# CBASS0_ISC register map
Vendor: Texas Instruments
Registers are 32-bit, read-write, reset 0x0 unless marked. A register's access mark holds for its fields unless they carry their own. Offsets are as the file gives them; [hi:lo] are bit positions; {n}, {i} and the like mark numbered series; 'fields as' and 'values as' point back to an identical list.

## CBASS0_ISC (part 2 of 2)
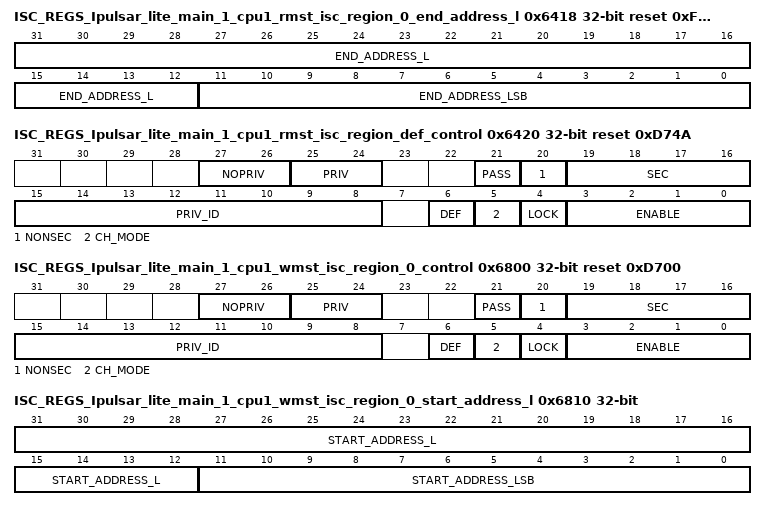
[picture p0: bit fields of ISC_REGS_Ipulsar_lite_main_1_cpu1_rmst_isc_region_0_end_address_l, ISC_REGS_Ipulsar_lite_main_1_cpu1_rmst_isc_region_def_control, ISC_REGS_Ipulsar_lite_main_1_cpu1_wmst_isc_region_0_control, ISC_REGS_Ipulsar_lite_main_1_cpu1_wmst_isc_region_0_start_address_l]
0x6418 ISC_REGS_Ipulsar_lite_main_1_cpu1_rmst_isc_region_0_end_address_l access per field reset 0xFFF — The ISC Region 0 End Address Low Register defines the end included address bits 31 to 0 for the master Ipulsar_lite_main_1.cpu1_rmst region 0 ISC.
  [31:12] END_ADDRESS_L rw — End address bits 31 to 12 to include in the match.
  [11:0] END_ADDRESS_LSB ro — End address bits 11 to 0 are forced to Fs as address must be 4KB aligned.
0x641C ISC_REGS_Ipulsar_lite_main_1_cpu1_rmst_isc_region_0_end_address_h — The ISC Region 0 End Address High Register defines the end address bits 47 to 32 for the master Ipulsar_lite_main_1.cpu1_rmst region 0 ISC.
  [15:0] END_ADDRESS_H — End address bits 47 to 32.
0x6420 ISC_REGS_Ipulsar_lite_main_1_cpu1_rmst_isc_region_def_control access not given reset 0xD74A — The ISC Default Region Control Register defines the control fields for the master Ipulsar_lite_main_1.cpu1_rmst region 1 ISC.
  [27:26] NOPRIV rw — Clear output priv attribute. If each bit is set then the outgoing priv bit is cleared, else the bit is unchanged. Do not set both priv and nopriv for the same bit.
  [25:24] PRIV rw — Set outgoing priv attribute. If each bit is set then the outgoing priv bit is set, else the bit is unchanged. Do not set both priv and nopriv for the same bit.
  [21] PASS rw — No privID replacement. A value of 1 will pass through privid value. A value of 0 will replace privid with priv_id field value.
  [20] NONSEC rw — Make outgoing non-secure. A value of 1 forces secure clear, others do nothing. Do not set both sec and nonsec.
  [19:16] SEC rw — Make outgoing secure. A value of 0xA forces secure set, others do nothing. Do not set both sec and nonsec.
  [15:8] PRIV_ID rw — Priv ID value to use if pass is 0.
  [6] DEF ro — Default region indication. The default region is used when all other regions do not match.
  [5] CH_MODE ro — Enable channel mode to match region to a chanid value. Otherwise use address mode to match region to an address range.
  [4] LOCK — Lock region. Once set, the region values cannot be modified. (access R/W1TS)
  [3:0] ENABLE ro — Enable region. A value of 0xA enables, others disable.
0x6800 ISC_REGS_Ipulsar_lite_main_1_cpu1_wmst_isc_region_0_control access not given reset 0xD700 — The ISC Region 0 Control Register defines the control fields for the master Ipulsar_lite_main_1.cpu1_wmst region 0 ISC.
  [27:26] NOPRIV rw — Clear output priv attribute. If each bit is set then the outgoing priv bit is cleared.
  [25:24] PRIV rw — Set outgoing priv attribute. If each bit is set then the outgoing priv bit is set.
  [21] PASS rw — No privID replacement, pass through value.
  [20] NONSEC rw — Make outgoing non-secure.
  [19:16] SEC rw — Make outgoing secure. A value of 0xA enables, others disable.
  [15:8] PRIV_ID rw
  [6] DEF ro — Default region indication. The default region is used when all other regions do not match.
  [5] CH_MODE rw — Enable channel mode to match region to a chanid value. Otherwise use address mode to match region to an address range.
  [4] LOCK — Lock region. Once set the region values cannot be modified. (access R/W1TS)
  [3:0] ENABLE rw — Enable region. A value of 0xA enables, others disable.
0x6810 ISC_REGS_Ipulsar_lite_main_1_cpu1_wmst_isc_region_0_start_address_l — The ISC Region 0 Start Address Low Register defines the start address bits 31 to 0 for the master Ipulsar_lite_main_1.cpu1_wmst region 0 ISC.
  [31:12] START_ADDRESS_L — Start address bits 31 to 12.
  [11:0] START_ADDRESS_LSB — Start address bits 11 to 0 must be 0 as address must be 4KB aligned in address mode. Can also be channel number in channel mode.
0x6814 ISC_REGS_Ipulsar_lite_main_1_cpu1_wmst_isc_region_0_start_address_h — The ISC Region 0 Start Address High Register defines the start address bits 47 to 32 for the master Ipulsar_lite_main_1.cpu1_wmst region 0 ISC.
  [15:0] START_ADDRESS_H — Start address bits 47 to 32.
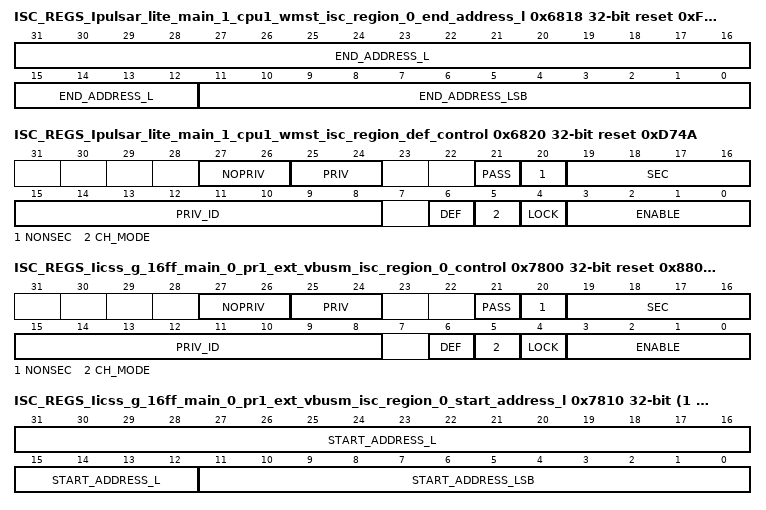
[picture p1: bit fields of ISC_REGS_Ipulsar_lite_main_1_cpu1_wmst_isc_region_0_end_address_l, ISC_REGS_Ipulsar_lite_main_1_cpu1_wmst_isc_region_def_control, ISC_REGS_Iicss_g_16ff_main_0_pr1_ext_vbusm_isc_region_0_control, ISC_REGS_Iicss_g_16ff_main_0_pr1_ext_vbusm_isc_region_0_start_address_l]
0x6818 ISC_REGS_Ipulsar_lite_main_1_cpu1_wmst_isc_region_0_end_address_l access per field reset 0xFFF — The ISC Region 0 End Address Low Register defines the end included address bits 31 to 0 for the master Ipulsar_lite_main_1.cpu1_wmst region 0 ISC.
  fields as ISC_REGS_Ipulsar_lite_main_1_cpu1_rmst_isc_region_0_end_address_l
0x681C ISC_REGS_Ipulsar_lite_main_1_cpu1_wmst_isc_region_0_end_address_h — The ISC Region 0 End Address High Register defines the end address bits 47 to 32 for the master Ipulsar_lite_main_1.cpu1_wmst region 0 ISC.
  [15:0] END_ADDRESS_H — End address bits 47 to 32.
0x6820 ISC_REGS_Ipulsar_lite_main_1_cpu1_wmst_isc_region_def_control access not given reset 0xD74A — The ISC Default Region Control Register defines the control fields for the master Ipulsar_lite_main_1.cpu1_wmst region 1 ISC.
  fields as ISC_REGS_Ipulsar_lite_main_1_cpu1_rmst_isc_region_def_control
{0x7800+0x20*i} ISC_REGS_Iicss_g_16ff_main_0_pr1_ext_vbusm_isc_region_{i}_control access not given reset 0x8800 (i=0..15) — The ISC Region {i} Control Register defines the control fields for the master Iicss_g_16ff_main_0.pr1_ext_vbusm region {i} ISC.
  fields as ISC_REGS_Ipulsar_lite_main_1_cpu1_wmst_isc_region_0_control
{0x7810+0x20*i} ISC_REGS_Iicss_g_16ff_main_0_pr1_ext_vbusm_isc_region_{i}_start_address_l (i=0..15) — The ISC Region {i} Start Address Low Register defines the start address bits 31 to 0 for the master Iicss_g_16ff_main_0.pr1_ext_vbusm region {i} ISC.
  fields as ISC_REGS_Ipulsar_lite_main_1_cpu1_wmst_isc_region_0_start_address_l
{0x7814+0x20*i} ISC_REGS_Iicss_g_16ff_main_0_pr1_ext_vbusm_isc_region_{i}_start_address_h (i=0..15) — The ISC Region {i} Start Address High Register defines the start address bits 47 to 32 for the master Iicss_g_16ff_main_0.pr1_ext_vbusm region {i} ISC.
  [15:0] START_ADDRESS_H — Start address bits 47 to 32.
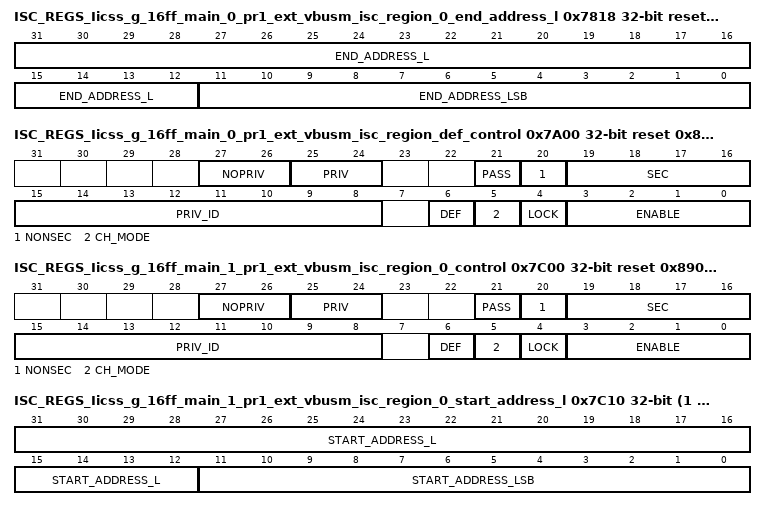
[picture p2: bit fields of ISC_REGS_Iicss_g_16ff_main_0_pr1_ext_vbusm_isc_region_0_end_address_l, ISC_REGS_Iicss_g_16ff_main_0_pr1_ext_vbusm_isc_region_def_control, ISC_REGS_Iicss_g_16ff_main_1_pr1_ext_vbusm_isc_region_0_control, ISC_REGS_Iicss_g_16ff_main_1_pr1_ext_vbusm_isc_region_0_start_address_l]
{0x7818+0x20*i} ISC_REGS_Iicss_g_16ff_main_0_pr1_ext_vbusm_isc_region_{i}_end_address_l access per field reset 0xFFF (i=0..15) — The ISC Region {i} End Address Low Register defines the end included address bits 31 to 0 for the master Iicss_g_16ff_main_0.pr1_ext_vbusm region {i} ISC.
  fields as ISC_REGS_Ipulsar_lite_main_1_cpu1_rmst_isc_region_0_end_address_l
{0x781C+0x20*i} ISC_REGS_Iicss_g_16ff_main_0_pr1_ext_vbusm_isc_region_{i}_end_address_h (i=0..15) — The ISC Region {i} End Address High Register defines the end address bits 47 to 32 for the master Iicss_g_16ff_main_0.pr1_ext_vbusm region {i} ISC.
  [15:0] END_ADDRESS_H — End address bits 47 to 32.
0x7A00 ISC_REGS_Iicss_g_16ff_main_0_pr1_ext_vbusm_isc_region_def_control access not given reset 0x884A — The ISC Default Region Control Register defines the control fields for the master Iicss_g_16ff_main_0.pr1_ext_vbusm region 16 ISC.
  fields as ISC_REGS_Ipulsar_lite_main_1_cpu1_rmst_isc_region_def_control
{0x7C00+0x20*i} ISC_REGS_Iicss_g_16ff_main_1_pr1_ext_vbusm_isc_region_{i}_control access not given reset 0x8900 (i=0..15) — The ISC Region {i} Control Register defines the control fields for the master Iicss_g_16ff_main_1.pr1_ext_vbusm region {i} ISC.
  fields as ISC_REGS_Ipulsar_lite_main_1_cpu1_wmst_isc_region_0_control
{0x7C10+0x20*i} ISC_REGS_Iicss_g_16ff_main_1_pr1_ext_vbusm_isc_region_{i}_start_address_l (i=0..15) — The ISC Region {i} Start Address Low Register defines the start address bits 31 to 0 for the master Iicss_g_16ff_main_1.pr1_ext_vbusm region {i} ISC.
  fields as ISC_REGS_Ipulsar_lite_main_1_cpu1_wmst_isc_region_0_start_address_l
{0x7C14+0x20*i} ISC_REGS_Iicss_g_16ff_main_1_pr1_ext_vbusm_isc_region_{i}_start_address_h (i=0..15) — The ISC Region {i} Start Address High Register defines the start address bits 47 to 32 for the master Iicss_g_16ff_main_1.pr1_ext_vbusm region {i} ISC.
  [15:0] START_ADDRESS_H — Start address bits 47 to 32.
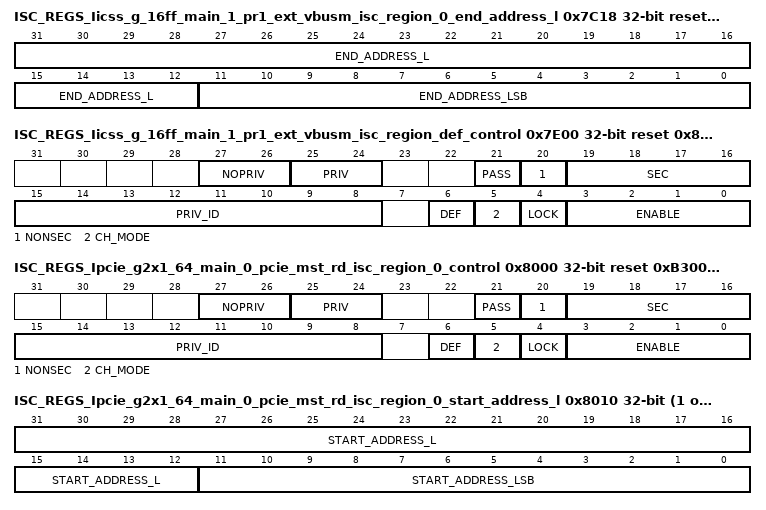
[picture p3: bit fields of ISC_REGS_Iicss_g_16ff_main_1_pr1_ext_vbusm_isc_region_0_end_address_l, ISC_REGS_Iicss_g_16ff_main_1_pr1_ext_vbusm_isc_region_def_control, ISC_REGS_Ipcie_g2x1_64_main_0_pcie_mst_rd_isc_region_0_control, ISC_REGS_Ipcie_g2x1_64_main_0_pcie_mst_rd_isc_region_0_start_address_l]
{0x7C18+0x20*i} ISC_REGS_Iicss_g_16ff_main_1_pr1_ext_vbusm_isc_region_{i}_end_address_l access per field reset 0xFFF (i=0..15) — The ISC Region {i} End Address Low Register defines the end included address bits 31 to 0 for the master Iicss_g_16ff_main_1.pr1_ext_vbusm region {i} ISC.
  fields as ISC_REGS_Ipulsar_lite_main_1_cpu1_rmst_isc_region_0_end_address_l
{0x7C1C+0x20*i} ISC_REGS_Iicss_g_16ff_main_1_pr1_ext_vbusm_isc_region_{i}_end_address_h (i=0..15) — The ISC Region {i} End Address High Register defines the end address bits 47 to 32 for the master Iicss_g_16ff_main_1.pr1_ext_vbusm region {i} ISC.
  [15:0] END_ADDRESS_H — End address bits 47 to 32.
0x7E00 ISC_REGS_Iicss_g_16ff_main_1_pr1_ext_vbusm_isc_region_def_control access not given reset 0x894A — The ISC Default Region Control Register defines the control fields for the master Iicss_g_16ff_main_1.pr1_ext_vbusm region 16 ISC.
  fields as ISC_REGS_Ipulsar_lite_main_1_cpu1_rmst_isc_region_def_control
{0x8000+0x20*i} ISC_REGS_Ipcie_g2x1_64_main_0_pcie_mst_rd_isc_region_{i}_control access not given reset 0xB300 (i=0..7) — The ISC Region {i} Control Register defines the control fields for the master Ipcie_g2x1_64_main_0.pcie_mst_rd region {i} ISC.
  fields as ISC_REGS_Ipulsar_lite_main_1_cpu1_wmst_isc_region_0_control
{0x8010+0x20*i} ISC_REGS_Ipcie_g2x1_64_main_0_pcie_mst_rd_isc_region_{i}_start_address_l (i=0..7) — The ISC Region {i} Start Address Low Register defines the start address bits 31 to 0 for the master Ipcie_g2x1_64_main_0.pcie_mst_rd region {i} ISC.
  fields as ISC_REGS_Ipulsar_lite_main_1_cpu1_wmst_isc_region_0_start_address_l
{0x8014+0x20*i} ISC_REGS_Ipcie_g2x1_64_main_0_pcie_mst_rd_isc_region_{i}_start_address_h (i=0..7) — The ISC Region {i} Start Address High Register defines the start address bits 47 to 32 for the master Ipcie_g2x1_64_main_0.pcie_mst_rd region {i} ISC.
  [15:0] START_ADDRESS_H — Start address bits 47 to 32.
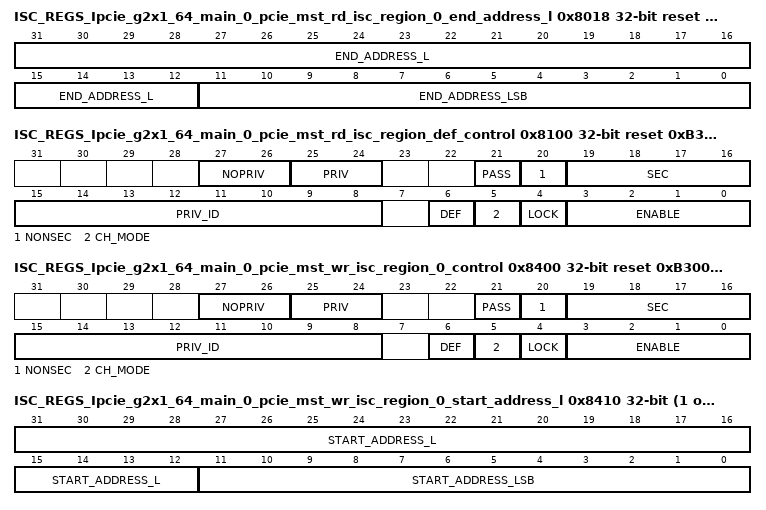
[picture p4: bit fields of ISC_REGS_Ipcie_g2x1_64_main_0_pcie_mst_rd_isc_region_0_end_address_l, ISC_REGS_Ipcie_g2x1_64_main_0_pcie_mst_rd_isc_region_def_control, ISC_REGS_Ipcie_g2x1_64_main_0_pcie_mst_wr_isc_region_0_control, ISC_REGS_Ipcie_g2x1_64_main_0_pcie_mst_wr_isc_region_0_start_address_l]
{0x8018+0x20*i} ISC_REGS_Ipcie_g2x1_64_main_0_pcie_mst_rd_isc_region_{i}_end_address_l access per field reset 0xFFF (i=0..7) — The ISC Region {i} End Address Low Register defines the end included address bits 31 to 0 for the master Ipcie_g2x1_64_main_0.pcie_mst_rd region {i} ISC.
  fields as ISC_REGS_Ipulsar_lite_main_1_cpu1_rmst_isc_region_0_end_address_l
{0x801C+0x20*i} ISC_REGS_Ipcie_g2x1_64_main_0_pcie_mst_rd_isc_region_{i}_end_address_h (i=0..7) — The ISC Region {i} End Address High Register defines the end address bits 47 to 32 for the master Ipcie_g2x1_64_main_0.pcie_mst_rd region {i} ISC.
  [15:0] END_ADDRESS_H — End address bits 47 to 32.
0x8100 ISC_REGS_Ipcie_g2x1_64_main_0_pcie_mst_rd_isc_region_def_control access not given reset 0xB34A — The ISC Default Region Control Register defines the control fields for the master Ipcie_g2x1_64_main_0.pcie_mst_rd region 8 ISC.
  fields as ISC_REGS_Ipulsar_lite_main_1_cpu1_rmst_isc_region_def_control
{0x8400+0x20*i} ISC_REGS_Ipcie_g2x1_64_main_0_pcie_mst_wr_isc_region_{i}_control access not given reset 0xB300 (i=0..7) — The ISC Region {i} Control Register defines the control fields for the master Ipcie_g2x1_64_main_0.pcie_mst_wr region {i} ISC.
  fields as ISC_REGS_Ipulsar_lite_main_1_cpu1_wmst_isc_region_0_control
{0x8410+0x20*i} ISC_REGS_Ipcie_g2x1_64_main_0_pcie_mst_wr_isc_region_{i}_start_address_l (i=0..7) — The ISC Region {i} Start Address Low Register defines the start address bits 31 to 0 for the master Ipcie_g2x1_64_main_0.pcie_mst_wr region {i} ISC.
  fields as ISC_REGS_Ipulsar_lite_main_1_cpu1_wmst_isc_region_0_start_address_l
{0x8414+0x20*i} ISC_REGS_Ipcie_g2x1_64_main_0_pcie_mst_wr_isc_region_{i}_start_address_h (i=0..7) — The ISC Region {i} Start Address High Register defines the start address bits 47 to 32 for the master Ipcie_g2x1_64_main_0.pcie_mst_wr region {i} ISC.
  [15:0] START_ADDRESS_H — Start address bits 47 to 32.
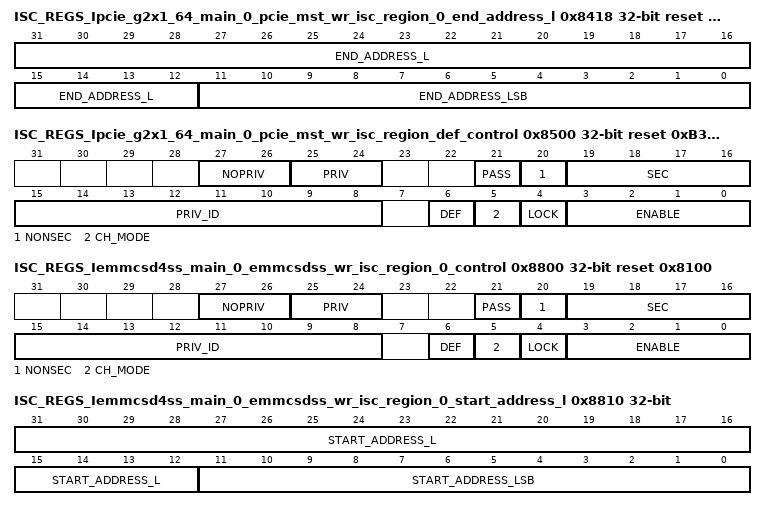
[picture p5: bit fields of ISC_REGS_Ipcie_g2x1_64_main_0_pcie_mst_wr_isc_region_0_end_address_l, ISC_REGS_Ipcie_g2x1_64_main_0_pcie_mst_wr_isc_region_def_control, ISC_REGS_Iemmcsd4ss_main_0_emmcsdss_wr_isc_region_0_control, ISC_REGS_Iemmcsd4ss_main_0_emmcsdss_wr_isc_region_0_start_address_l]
{0x8418+0x20*i} ISC_REGS_Ipcie_g2x1_64_main_0_pcie_mst_wr_isc_region_{i}_end_address_l access per field reset 0xFFF (i=0..7) — The ISC Region {i} End Address Low Register defines the end included address bits 31 to 0 for the master Ipcie_g2x1_64_main_0.pcie_mst_wr region {i} ISC.
  fields as ISC_REGS_Ipulsar_lite_main_1_cpu1_rmst_isc_region_0_end_address_l
{0x841C+0x20*i} ISC_REGS_Ipcie_g2x1_64_main_0_pcie_mst_wr_isc_region_{i}_end_address_h (i=0..7) — The ISC Region {i} End Address High Register defines the end address bits 47 to 32 for the master Ipcie_g2x1_64_main_0.pcie_mst_wr region {i} ISC.
  [15:0] END_ADDRESS_H — End address bits 47 to 32.
0x8500 ISC_REGS_Ipcie_g2x1_64_main_0_pcie_mst_wr_isc_region_def_control access not given reset 0xB34A — The ISC Default Region Control Register defines the control fields for the master Ipcie_g2x1_64_main_0.pcie_mst_wr region 8 ISC.
  fields as ISC_REGS_Ipulsar_lite_main_1_cpu1_rmst_isc_region_def_control
0x8800 ISC_REGS_Iemmcsd4ss_main_0_emmcsdss_wr_isc_region_0_control access not given reset 0x8100 — The ISC Region 0 Control Register defines the control fields for the master Iemmcsd4ss_main_0.emmcsdss_wr region 0 ISC.
  fields as ISC_REGS_Ipulsar_lite_main_1_cpu1_wmst_isc_region_0_control
0x8810 ISC_REGS_Iemmcsd4ss_main_0_emmcsdss_wr_isc_region_0_start_address_l — The ISC Region 0 Start Address Low Register defines the start address bits 31 to 0 for the master Iemmcsd4ss_main_0.emmcsdss_wr region 0 ISC.
  fields as ISC_REGS_Ipulsar_lite_main_1_cpu1_wmst_isc_region_0_start_address_l
0x8814 ISC_REGS_Iemmcsd4ss_main_0_emmcsdss_wr_isc_region_0_start_address_h — The ISC Region 0 Start Address High Register defines the start address bits 47 to 32 for the master Iemmcsd4ss_main_0.emmcsdss_wr region 0 ISC.
  [15:0] START_ADDRESS_H — Start address bits 47 to 32.
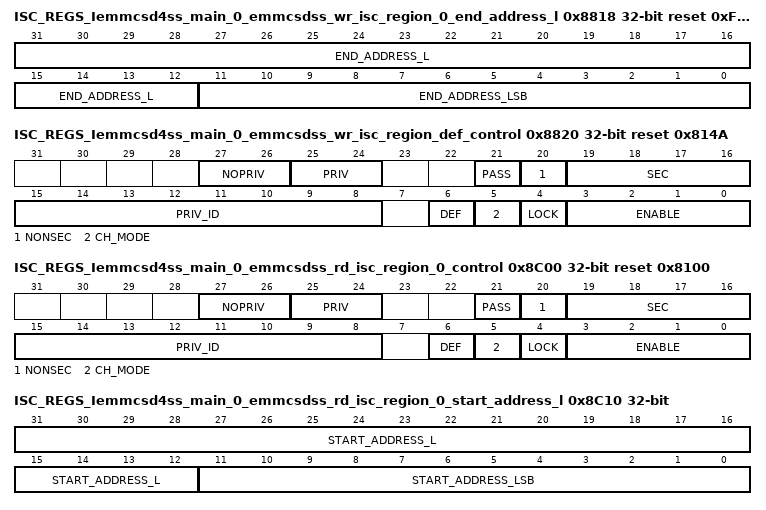
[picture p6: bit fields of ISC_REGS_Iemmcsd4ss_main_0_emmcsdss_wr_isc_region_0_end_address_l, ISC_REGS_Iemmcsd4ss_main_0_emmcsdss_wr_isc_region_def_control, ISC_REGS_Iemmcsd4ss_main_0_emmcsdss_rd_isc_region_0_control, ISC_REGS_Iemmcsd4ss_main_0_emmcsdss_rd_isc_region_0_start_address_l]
0x8818 ISC_REGS_Iemmcsd4ss_main_0_emmcsdss_wr_isc_region_0_end_address_l access per field reset 0xFFF — The ISC Region 0 End Address Low Register defines the end included address bits 31 to 0 for the master Iemmcsd4ss_main_0.emmcsdss_wr region 0 ISC.
  fields as ISC_REGS_Ipulsar_lite_main_1_cpu1_rmst_isc_region_0_end_address_l
0x881C ISC_REGS_Iemmcsd4ss_main_0_emmcsdss_wr_isc_region_0_end_address_h — The ISC Region 0 End Address High Register defines the end address bits 47 to 32 for the master Iemmcsd4ss_main_0.emmcsdss_wr region 0 ISC.
  [15:0] END_ADDRESS_H — End address bits 47 to 32.
0x8820 ISC_REGS_Iemmcsd4ss_main_0_emmcsdss_wr_isc_region_def_control access not given reset 0x814A — The ISC Default Region Control Register defines the control fields for the master Iemmcsd4ss_main_0.emmcsdss_wr region 1 ISC.
  fields as ISC_REGS_Ipulsar_lite_main_1_cpu1_rmst_isc_region_def_control
0x8C00 ISC_REGS_Iemmcsd4ss_main_0_emmcsdss_rd_isc_region_0_control access not given reset 0x8100 — The ISC Region 0 Control Register defines the control fields for the master Iemmcsd4ss_main_0.emmcsdss_rd region 0 ISC.
  fields as ISC_REGS_Ipulsar_lite_main_1_cpu1_wmst_isc_region_0_control
0x8C10 ISC_REGS_Iemmcsd4ss_main_0_emmcsdss_rd_isc_region_0_start_address_l — The ISC Region 0 Start Address Low Register defines the start address bits 31 to 0 for the master Iemmcsd4ss_main_0.emmcsdss_rd region 0 ISC.
  fields as ISC_REGS_Ipulsar_lite_main_1_cpu1_wmst_isc_region_0_start_address_l
0x8C14 ISC_REGS_Iemmcsd4ss_main_0_emmcsdss_rd_isc_region_0_start_address_h — The ISC Region 0 Start Address High Register defines the start address bits 47 to 32 for the master Iemmcsd4ss_main_0.emmcsdss_rd region 0 ISC.
  [15:0] START_ADDRESS_H — Start address bits 47 to 32.
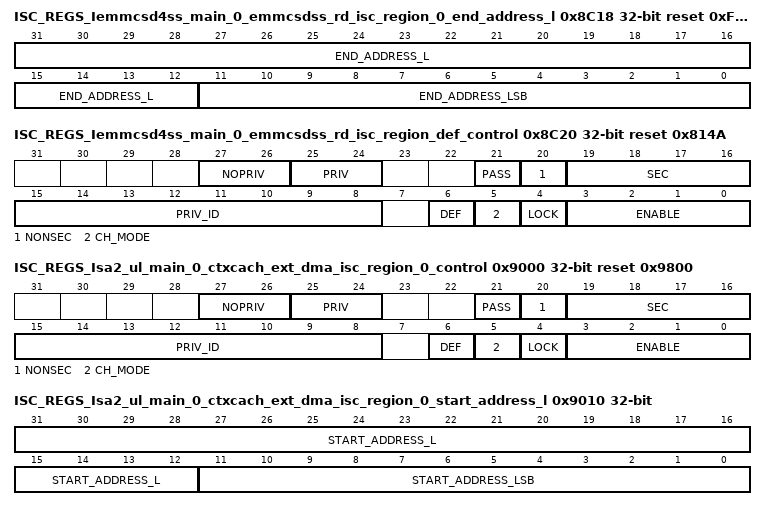
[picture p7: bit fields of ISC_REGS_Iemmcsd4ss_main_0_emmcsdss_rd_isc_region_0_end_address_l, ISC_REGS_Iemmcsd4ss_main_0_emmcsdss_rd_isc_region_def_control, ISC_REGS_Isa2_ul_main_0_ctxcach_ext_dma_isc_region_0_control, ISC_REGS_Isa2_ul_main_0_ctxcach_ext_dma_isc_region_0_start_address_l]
0x8C18 ISC_REGS_Iemmcsd4ss_main_0_emmcsdss_rd_isc_region_0_end_address_l access per field reset 0xFFF — The ISC Region 0 End Address Low Register defines the end included address bits 31 to 0 for the master Iemmcsd4ss_main_0.emmcsdss_rd region 0 ISC.
  fields as ISC_REGS_Ipulsar_lite_main_1_cpu1_rmst_isc_region_0_end_address_l
0x8C1C ISC_REGS_Iemmcsd4ss_main_0_emmcsdss_rd_isc_region_0_end_address_h — The ISC Region 0 End Address High Register defines the end address bits 47 to 32 for the master Iemmcsd4ss_main_0.emmcsdss_rd region 0 ISC.
  [15:0] END_ADDRESS_H — End address bits 47 to 32.
0x8C20 ISC_REGS_Iemmcsd4ss_main_0_emmcsdss_rd_isc_region_def_control access not given reset 0x814A — The ISC Default Region Control Register defines the control fields for the master Iemmcsd4ss_main_0.emmcsdss_rd region 1 ISC.
  fields as ISC_REGS_Ipulsar_lite_main_1_cpu1_rmst_isc_region_def_control
0x9000 ISC_REGS_Isa2_ul_main_0_ctxcach_ext_dma_isc_region_0_control access not given reset 0x9800 — The ISC Region 0 Control Register defines the control fields for the master Isa2_ul_main_0.ctxcach_ext_dma region 0 ISC.
  fields as ISC_REGS_Ipulsar_lite_main_1_cpu1_wmst_isc_region_0_control
0x9010 ISC_REGS_Isa2_ul_main_0_ctxcach_ext_dma_isc_region_0_start_address_l — The ISC Region 0 Start Address Low Register defines the start address bits 31 to 0 for the master Isa2_ul_main_0.ctxcach_ext_dma region 0 ISC.
  fields as ISC_REGS_Ipulsar_lite_main_1_cpu1_wmst_isc_region_0_start_address_l
0x9014 ISC_REGS_Isa2_ul_main_0_ctxcach_ext_dma_isc_region_0_start_address_h — The ISC Region 0 Start Address High Register defines the start address bits 47 to 32 for the master Isa2_ul_main_0.ctxcach_ext_dma region 0 ISC.
  [15:0] START_ADDRESS_H — Start address bits 47 to 32.
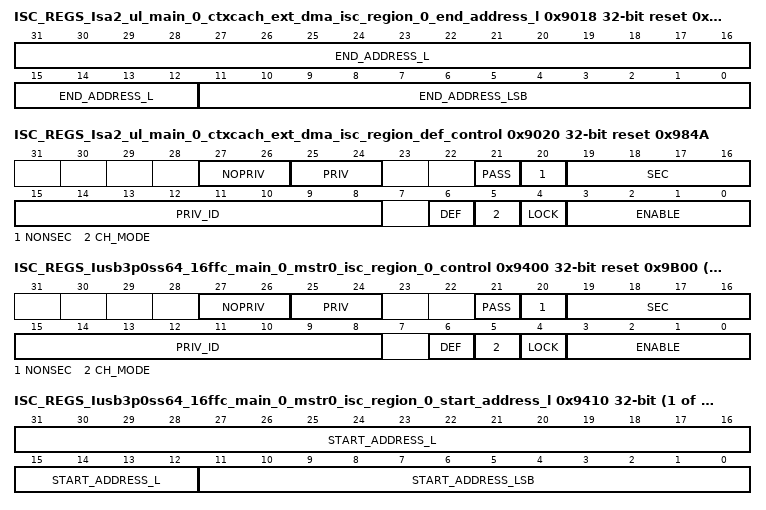
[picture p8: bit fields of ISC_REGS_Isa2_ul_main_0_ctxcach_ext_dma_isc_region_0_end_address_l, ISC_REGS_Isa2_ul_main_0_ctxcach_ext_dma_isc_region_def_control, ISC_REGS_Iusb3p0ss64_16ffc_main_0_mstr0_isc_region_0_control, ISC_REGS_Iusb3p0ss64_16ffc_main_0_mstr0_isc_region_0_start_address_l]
0x9018 ISC_REGS_Isa2_ul_main_0_ctxcach_ext_dma_isc_region_0_end_address_l access per field reset 0xFFF — The ISC Region 0 End Address Low Register defines the end included address bits 31 to 0 for the master Isa2_ul_main_0.ctxcach_ext_dma region 0 ISC.
  fields as ISC_REGS_Ipulsar_lite_main_1_cpu1_rmst_isc_region_0_end_address_l
0x901C ISC_REGS_Isa2_ul_main_0_ctxcach_ext_dma_isc_region_0_end_address_h — The ISC Region 0 End Address High Register defines the end address bits 47 to 32 for the master Isa2_ul_main_0.ctxcach_ext_dma region 0 ISC.
  [15:0] END_ADDRESS_H — End address bits 47 to 32.
0x9020 ISC_REGS_Isa2_ul_main_0_ctxcach_ext_dma_isc_region_def_control access not given reset 0x984A — The ISC Default Region Control Register defines the control fields for the master Isa2_ul_main_0.ctxcach_ext_dma region 1 ISC.
  fields as ISC_REGS_Ipulsar_lite_main_1_cpu1_rmst_isc_region_def_control
{0x9400+0x20*i} ISC_REGS_Iusb3p0ss64_16ffc_main_0_mstr0_isc_region_{i}_control access not given reset 0x9B00 (i=0..7) — The ISC Region {i} Control Register defines the control fields for the master Iusb3p0ss64_16ffc_main_0.mstr0 region {i} ISC.
  fields as ISC_REGS_Ipulsar_lite_main_1_cpu1_wmst_isc_region_0_control
{0x9410+0x20*i} ISC_REGS_Iusb3p0ss64_16ffc_main_0_mstr0_isc_region_{i}_start_address_l (i=0..7) — The ISC Region {i} Start Address Low Register defines the start address bits 31 to 0 for the master Iusb3p0ss64_16ffc_main_0.mstr0 region {i} ISC.
  fields as ISC_REGS_Ipulsar_lite_main_1_cpu1_wmst_isc_region_0_start_address_l
{0x9414+0x20*i} ISC_REGS_Iusb3p0ss64_16ffc_main_0_mstr0_isc_region_{i}_start_address_h (i=0..7) — The ISC Region {i} Start Address High Register defines the start address bits 47 to 32 for the master Iusb3p0ss64_16ffc_main_0.mstr0 region {i} ISC.
  [15:0] START_ADDRESS_H — Start address bits 47 to 32.
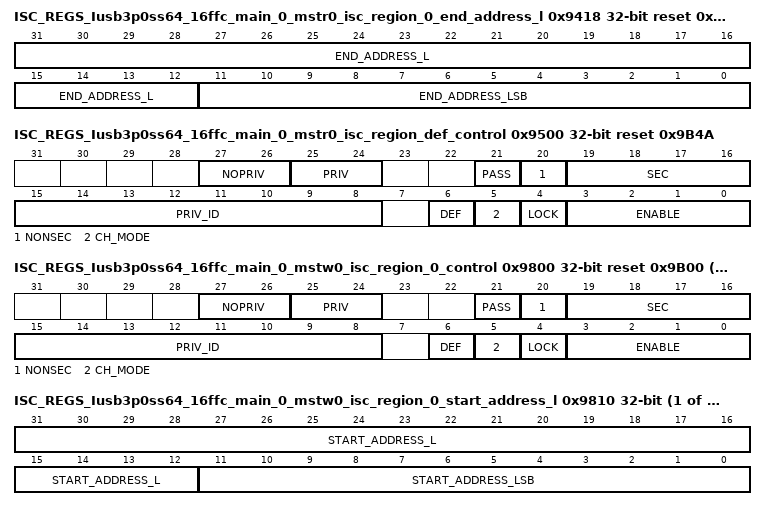
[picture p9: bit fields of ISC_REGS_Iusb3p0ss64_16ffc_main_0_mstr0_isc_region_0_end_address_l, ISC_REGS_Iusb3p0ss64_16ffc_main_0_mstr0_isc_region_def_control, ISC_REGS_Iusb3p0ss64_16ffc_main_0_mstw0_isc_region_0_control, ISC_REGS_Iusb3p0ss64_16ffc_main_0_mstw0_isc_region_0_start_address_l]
{0x9418+0x20*i} ISC_REGS_Iusb3p0ss64_16ffc_main_0_mstr0_isc_region_{i}_end_address_l access per field reset 0xFFF (i=0..7) — The ISC Region {i} End Address Low Register defines the end included address bits 31 to 0 for the master Iusb3p0ss64_16ffc_main_0.mstr0 region {i} ISC.
  fields as ISC_REGS_Ipulsar_lite_main_1_cpu1_rmst_isc_region_0_end_address_l
{0x941C+0x20*i} ISC_REGS_Iusb3p0ss64_16ffc_main_0_mstr0_isc_region_{i}_end_address_h (i=0..7) — The ISC Region {i} End Address High Register defines the end address bits 47 to 32 for the master Iusb3p0ss64_16ffc_main_0.mstr0 region {i} ISC.
  [15:0] END_ADDRESS_H — End address bits 47 to 32.
0x9500 ISC_REGS_Iusb3p0ss64_16ffc_main_0_mstr0_isc_region_def_control access not given reset 0x9B4A — The ISC Default Region Control Register defines the control fields for the master Iusb3p0ss64_16ffc_main_0.mstr0 region 8 ISC.
  fields as ISC_REGS_Ipulsar_lite_main_1_cpu1_rmst_isc_region_def_control
{0x9800+0x20*i} ISC_REGS_Iusb3p0ss64_16ffc_main_0_mstw0_isc_region_{i}_control access not given reset 0x9B00 (i=0..7) — The ISC Region {i} Control Register defines the control fields for the master Iusb3p0ss64_16ffc_main_0.mstw0 region {i} ISC.
  fields as ISC_REGS_Ipulsar_lite_main_1_cpu1_wmst_isc_region_0_control
{0x9810+0x20*i} ISC_REGS_Iusb3p0ss64_16ffc_main_0_mstw0_isc_region_{i}_start_address_l (i=0..7) — The ISC Region {i} Start Address Low Register defines the start address bits 31 to 0 for the master Iusb3p0ss64_16ffc_main_0.mstw0 region {i} ISC.
  fields as ISC_REGS_Ipulsar_lite_main_1_cpu1_wmst_isc_region_0_start_address_l
{0x9814+0x20*i} ISC_REGS_Iusb3p0ss64_16ffc_main_0_mstw0_isc_region_{i}_start_address_h (i=0..7) — The ISC Region {i} Start Address High Register defines the start address bits 47 to 32 for the master Iusb3p0ss64_16ffc_main_0.mstw0 region {i} ISC.
  [15:0] START_ADDRESS_H — Start address bits 47 to 32.
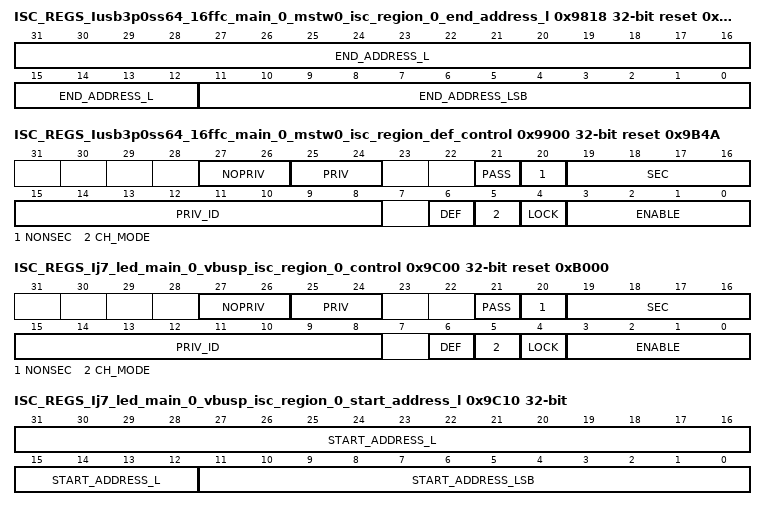
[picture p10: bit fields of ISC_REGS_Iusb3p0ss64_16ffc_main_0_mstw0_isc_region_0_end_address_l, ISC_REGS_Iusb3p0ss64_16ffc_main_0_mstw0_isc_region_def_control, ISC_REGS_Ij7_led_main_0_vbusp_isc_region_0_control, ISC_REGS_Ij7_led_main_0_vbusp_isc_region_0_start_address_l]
{0x9818+0x20*i} ISC_REGS_Iusb3p0ss64_16ffc_main_0_mstw0_isc_region_{i}_end_address_l access per field reset 0xFFF (i=0..7) — The ISC Region {i} End Address Low Register defines the end included address bits 31 to 0 for the master Iusb3p0ss64_16ffc_main_0.mstw0 region {i} ISC.
  fields as ISC_REGS_Ipulsar_lite_main_1_cpu1_rmst_isc_region_0_end_address_l
{0x981C+0x20*i} ISC_REGS_Iusb3p0ss64_16ffc_main_0_mstw0_isc_region_{i}_end_address_h (i=0..7) — The ISC Region {i} End Address High Register defines the end address bits 47 to 32 for the master Iusb3p0ss64_16ffc_main_0.mstw0 region {i} ISC.
  [15:0] END_ADDRESS_H — End address bits 47 to 32.
0x9900 ISC_REGS_Iusb3p0ss64_16ffc_main_0_mstw0_isc_region_def_control access not given reset 0x9B4A — The ISC Default Region Control Register defines the control fields for the master Iusb3p0ss64_16ffc_main_0.mstw0 region 8 ISC.
  fields as ISC_REGS_Ipulsar_lite_main_1_cpu1_rmst_isc_region_def_control
0x9C00 ISC_REGS_Ij7_led_main_0_vbusp_isc_region_0_control access not given reset 0xB000 — The ISC Region 0 Control Register defines the control fields for the master Ij7_led_main_0.vbusp region 0 ISC.
  fields as ISC_REGS_Ipulsar_lite_main_1_cpu1_wmst_isc_region_0_control
0x9C10 ISC_REGS_Ij7_led_main_0_vbusp_isc_region_0_start_address_l — The ISC Region 0 Start Address Low Register defines the start address bits 31 to 0 for the master Ij7_led_main_0.vbusp region 0 ISC.
  fields as ISC_REGS_Ipulsar_lite_main_1_cpu1_wmst_isc_region_0_start_address_l
0x9C14 ISC_REGS_Ij7_led_main_0_vbusp_isc_region_0_start_address_h — The ISC Region 0 Start Address High Register defines the start address bits 47 to 32 for the master Ij7_led_main_0.vbusp region 0 ISC.
  [15:0] START_ADDRESS_H — Start address bits 47 to 32.
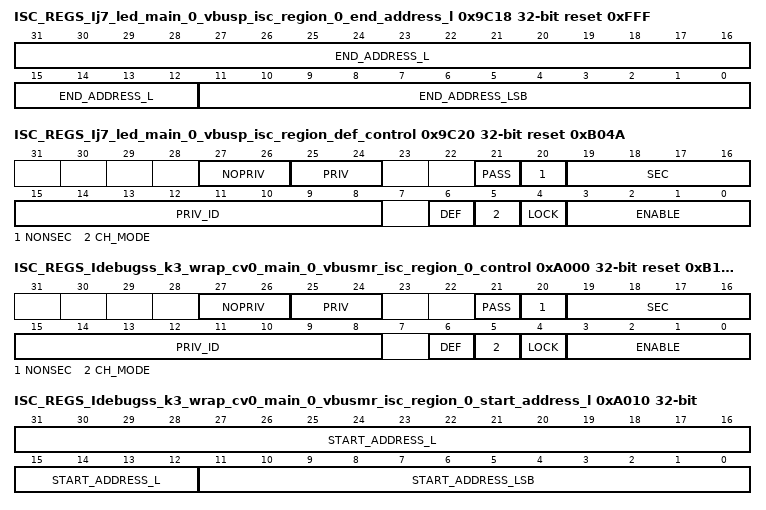
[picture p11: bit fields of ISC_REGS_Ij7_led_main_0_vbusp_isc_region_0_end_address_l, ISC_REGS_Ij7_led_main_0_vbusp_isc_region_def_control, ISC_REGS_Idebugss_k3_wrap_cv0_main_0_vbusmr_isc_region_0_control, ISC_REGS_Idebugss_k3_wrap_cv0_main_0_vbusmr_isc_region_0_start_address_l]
0x9C18 ISC_REGS_Ij7_led_main_0_vbusp_isc_region_0_end_address_l access per field reset 0xFFF — The ISC Region 0 End Address Low Register defines the end included address bits 31 to 0 for the master Ij7_led_main_0.vbusp region 0 ISC.
  fields as ISC_REGS_Ipulsar_lite_main_1_cpu1_rmst_isc_region_0_end_address_l
0x9C1C ISC_REGS_Ij7_led_main_0_vbusp_isc_region_0_end_address_h — The ISC Region 0 End Address High Register defines the end address bits 47 to 32 for the master Ij7_led_main_0.vbusp region 0 ISC.
  [15:0] END_ADDRESS_H — End address bits 47 to 32.
0x9C20 ISC_REGS_Ij7_led_main_0_vbusp_isc_region_def_control access not given reset 0xB04A — The ISC Default Region Control Register defines the control fields for the master Ij7_led_main_0.vbusp region 1 ISC.
  fields as ISC_REGS_Ipulsar_lite_main_1_cpu1_rmst_isc_region_def_control
0xA000 ISC_REGS_Idebugss_k3_wrap_cv0_main_0_vbusmr_isc_region_0_control access not given reset 0xB100 — The ISC Region 0 Control Register defines the control fields for the master Idebugss_k3_wrap_cv0_main_0.vbusmr region 0 ISC.
  fields as ISC_REGS_Ipulsar_lite_main_1_cpu1_wmst_isc_region_0_control
0xA010 ISC_REGS_Idebugss_k3_wrap_cv0_main_0_vbusmr_isc_region_0_start_address_l — The ISC Region 0 Start Address Low Register defines the start address bits 31 to 0 for the master Idebugss_k3_wrap_cv0_main_0.vbusmr region 0 ISC.
  fields as ISC_REGS_Ipulsar_lite_main_1_cpu1_wmst_isc_region_0_start_address_l
0xA014 ISC_REGS_Idebugss_k3_wrap_cv0_main_0_vbusmr_isc_region_0_start_address_h — The ISC Region 0 Start Address High Register defines the start address bits 47 to 32 for the master Idebugss_k3_wrap_cv0_main_0.vbusmr region 0 ISC.
  [15:0] START_ADDRESS_H — Start address bits 47 to 32.
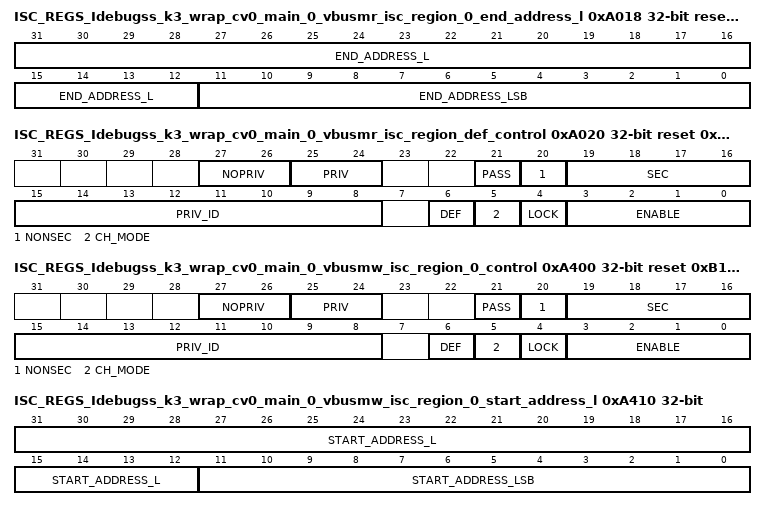
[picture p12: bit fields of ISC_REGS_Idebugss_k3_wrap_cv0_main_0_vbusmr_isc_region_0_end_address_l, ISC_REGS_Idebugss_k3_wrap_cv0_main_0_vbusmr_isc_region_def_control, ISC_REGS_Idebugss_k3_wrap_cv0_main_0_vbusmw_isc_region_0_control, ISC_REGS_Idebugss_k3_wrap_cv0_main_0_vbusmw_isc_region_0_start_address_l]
0xA018 ISC_REGS_Idebugss_k3_wrap_cv0_main_0_vbusmr_isc_region_0_end_address_l access per field reset 0xFFF — The ISC Region 0 End Address Low Register defines the end included address bits 31 to 0 for the master Idebugss_k3_wrap_cv0_main_0.vbusmr region 0 ISC.
  fields as ISC_REGS_Ipulsar_lite_main_1_cpu1_rmst_isc_region_0_end_address_l
0xA01C ISC_REGS_Idebugss_k3_wrap_cv0_main_0_vbusmr_isc_region_0_end_address_h — The ISC Region 0 End Address High Register defines the end address bits 47 to 32 for the master Idebugss_k3_wrap_cv0_main_0.vbusmr region 0 ISC.
  [15:0] END_ADDRESS_H — End address bits 47 to 32.
0xA020 ISC_REGS_Idebugss_k3_wrap_cv0_main_0_vbusmr_isc_region_def_control access not given reset 0xB14A — The ISC Default Region Control Register defines the control fields for the master Idebugss_k3_wrap_cv0_main_0.vbusmr region 1 ISC.
  fields as ISC_REGS_Ipulsar_lite_main_1_cpu1_rmst_isc_region_def_control
0xA400 ISC_REGS_Idebugss_k3_wrap_cv0_main_0_vbusmw_isc_region_0_control access not given reset 0xB100 — The ISC Region 0 Control Register defines the control fields for the master Idebugss_k3_wrap_cv0_main_0.vbusmw region 0 ISC.
  fields as ISC_REGS_Ipulsar_lite_main_1_cpu1_wmst_isc_region_0_control
0xA410 ISC_REGS_Idebugss_k3_wrap_cv0_main_0_vbusmw_isc_region_0_start_address_l — The ISC Region 0 Start Address Low Register defines the start address bits 31 to 0 for the master Idebugss_k3_wrap_cv0_main_0.vbusmw region 0 ISC.
  fields as ISC_REGS_Ipulsar_lite_main_1_cpu1_wmst_isc_region_0_start_address_l
0xA414 ISC_REGS_Idebugss_k3_wrap_cv0_main_0_vbusmw_isc_region_0_start_address_h — The ISC Region 0 Start Address High Register defines the start address bits 47 to 32 for the master Idebugss_k3_wrap_cv0_main_0.vbusmw region 0 ISC.
  [15:0] START_ADDRESS_H — Start address bits 47 to 32.
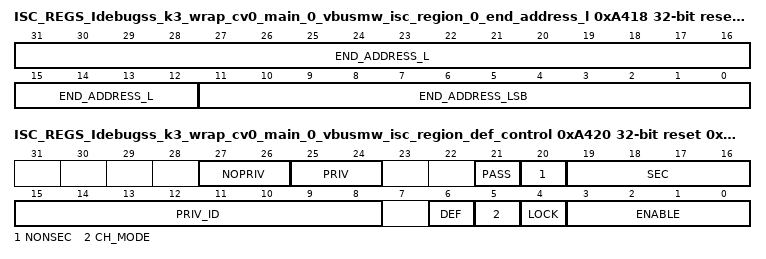
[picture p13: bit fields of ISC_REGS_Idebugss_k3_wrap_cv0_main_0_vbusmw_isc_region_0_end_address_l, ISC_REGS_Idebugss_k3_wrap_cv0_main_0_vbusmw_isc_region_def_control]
0xA418 ISC_REGS_Idebugss_k3_wrap_cv0_main_0_vbusmw_isc_region_0_end_address_l access per field reset 0xFFF — The ISC Region 0 End Address Low Register defines the end included address bits 31 to 0 for the master Idebugss_k3_wrap_cv0_main_0.vbusmw region 0 ISC.
  fields as ISC_REGS_Ipulsar_lite_main_1_cpu1_rmst_isc_region_0_end_address_l
0xA41C ISC_REGS_Idebugss_k3_wrap_cv0_main_0_vbusmw_isc_region_0_end_address_h — The ISC Region 0 End Address High Register defines the end address bits 47 to 32 for the master Idebugss_k3_wrap_cv0_main_0.vbusmw region 0 ISC.
  [15:0] END_ADDRESS_H — End address bits 47 to 32.
0xA420 ISC_REGS_Idebugss_k3_wrap_cv0_main_0_vbusmw_isc_region_def_control access not given reset 0xB14A — The ISC Default Region Control Register defines the control fields for the master Idebugss_k3_wrap_cv0_main_0.vbusmw region 1 ISC.
  fields as ISC_REGS_Ipulsar_lite_main_1_cpu1_rmst_isc_region_def_control
